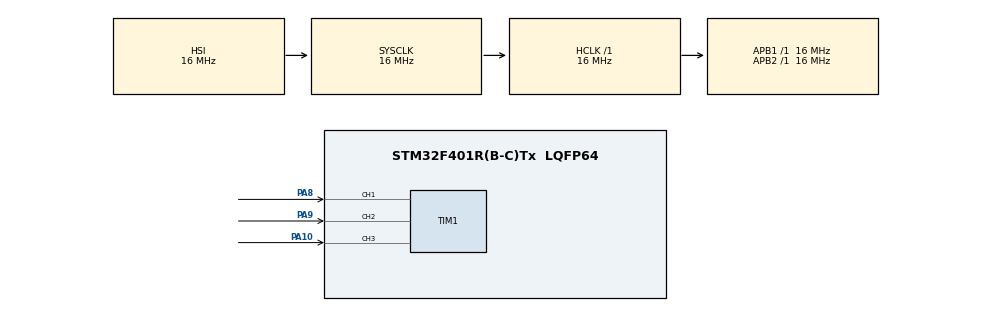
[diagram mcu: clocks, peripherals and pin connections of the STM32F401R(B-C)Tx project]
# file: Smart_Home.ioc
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Mcu.Family=STM32F4
Mcu.Name=STM32F401R(B-C)Tx
Mcu.Package=LQFP64
NVIC.PriorityGroup=NVIC_PRIORITYGROUP_4
PA10.Signal=S_TIM1_CH3
PA8.Signal=S_TIM1_CH1
PA9.Signal=S_TIM1_CH2
ProjectManager.HeapSize=0x200
ProjectManager.StackSize=0x400
ProjectManager.TargetToolchain=STM32CubeIDE
RCC.AHBFreq_Value=16000000
RCC.APB1Freq_Value=16000000
RCC.APB2Freq_Value=16000000
RCC.CortexFreq_Value=16000000
RCC.HSE_VALUE=25000000
RCC.HSI_VALUE=16000000
RCC.LSE_VALUE=32768
RCC.SYSCLKFreq_VALUE=16000000
RCC.VCOOutputFreq_Value=192000000
SH.S_TIM1_CH1.0=TIM1_CH1,Input_Capture1_from_TI1
SH.S_TIM1_CH2.0=TIM1_CH2,Input_Capture2_from_TI2
SH.S_TIM1_CH3.0=TIM1_CH3,Input_Capture3_from_TI3
TIM1.Channel-Input_Capture1_from_TI1=TIM_CHANNEL_1
TIM1.Channel-Input_Capture2_from_TI2=TIM_CHANNEL_2
TIM1.Channel-Input_Capture3_from_TI3=TIM_CHANNEL_3
VP_TIM1_VS_ClockSourceINT.Mode=Internal
board=custom

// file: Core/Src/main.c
/* USER CODE BEGIN Header */
/**
  ******************************************************************************
  * @file           : main.c
  * @brief          : Main program body
  ******************************************************************************
  * @attention
  *
  * Copyright (c) 2024 STMicroelectronics.
  * All rights reserved.
  *
  * This software is licensed under terms that can be found in the LICENSE file
  * in the root directory of this software component.
  * If no LICENSE file comes with this software, it is provided AS-IS.
  *
  ******************************************************************************
  */
/* USER CODE END Header */
#include "main.h"

/* USER CODE BEGIN Includes */

#include "ecu_layer_init.h"

/* USER CODE END Includes */

TIM_HandleTypeDef htim1;

/* USER CODE BEGIN PV */
extern const LED_t LED_CfgType;

Std_ReturnType ret_status = E_NOK;
/* USER CODE END PV */

void SystemClock_Config(void);
static void MX_GPIO_Init(void);
static void MX_TIM1_Init(void);

int main(void)
{

  /* MCU Configuration--------------------------------------------------------*/

  /* Reset of all peripherals, Initializes the Flash interface and the Systick. */
  HAL_Init();

  /* Configure the system clock */
  SystemClock_Config();

  /* Initialize all configured peripherals */
  MX_GPIO_Init();
  MX_TIM1_Init();
  /* USER CODE BEGIN 2 */
  ret_status = LED_Init(&LED_CfgType);
  /* USER CODE END 2 */

  /* Infinite loop */
  while (1)
  {

  }
}

void SystemClock_Config(void)
{
  RCC_OscInitTypeDef RCC_OscInitStruct = {0};
  RCC_ClkInitTypeDef RCC_ClkInitStruct = {0};

  /** Configure the main internal regulator output voltage
  */
  __HAL_RCC_PWR_CLK_ENABLE();
  __HAL_PWR_VOLTAGESCALING_CONFIG(PWR_REGULATOR_VOLTAGE_SCALE2);

  /** Initializes the RCC Oscillators according to the specified parameters
  * in the RCC_OscInitTypeDef structure.
  */
  RCC_OscInitStruct.OscillatorType = RCC_OSCILLATORTYPE_HSI;
  RCC_OscInitStruct.HSIState = RCC_HSI_ON;
  RCC_OscInitStruct.HSICalibrationValue = RCC_HSICALIBRATION_DEFAULT;
  RCC_OscInitStruct.PLL.PLLState = RCC_PLL_NONE;
  if (HAL_RCC_OscConfig(&RCC_OscInitStruct) != HAL_OK)
  {
    Error_Handler();
  }

  /** Initializes the CPU, AHB and APB buses clocks
  */
  RCC_ClkInitStruct.ClockType = RCC_CLOCKTYPE_HCLK|RCC_CLOCKTYPE_SYSCLK
                              |RCC_CLOCKTYPE_PCLK1|RCC_CLOCKTYPE_PCLK2;
  RCC_ClkInitStruct.SYSCLKSource = RCC_SYSCLKSOURCE_HSI;
  RCC_ClkInitStruct.AHBCLKDivider = RCC_SYSCLK_DIV1;
  RCC_ClkInitStruct.APB1CLKDivider = RCC_HCLK_DIV1;
  RCC_ClkInitStruct.APB2CLKDivider = RCC_HCLK_DIV1;

  if (HAL_RCC_ClockConfig(&RCC_ClkInitStruct, FLASH_LATENCY_0) != HAL_OK)
  {
    Error_Handler();
  }
}

static void MX_TIM1_Init(void)
{

  TIM_ClockConfigTypeDef sClockSourceConfig = {0};
  TIM_MasterConfigTypeDef sMasterConfig = {0};
  TIM_IC_InitTypeDef sConfigIC = {0};

  htim1.Instance = TIM1;
  htim1.Init.Prescaler = 0;
  htim1.Init.CounterMode = TIM_COUNTERMODE_UP;
  htim1.Init.Period = 65535;
  htim1.Init.ClockDivision = TIM_CLOCKDIVISION_DIV1;
  htim1.Init.RepetitionCounter = 0;
  htim1.Init.AutoReloadPreload = TIM_AUTORELOAD_PRELOAD_DISABLE;
  if (HAL_TIM_Base_Init(&htim1) != HAL_OK)
  {
    Error_Handler();
  }
  sClockSourceConfig.ClockSource = TIM_CLOCKSOURCE_INTERNAL;
  if (HAL_TIM_ConfigClockSource(&htim1, &sClockSourceConfig) != HAL_OK)
  {
    Error_Handler();
  }
  if (HAL_TIM_IC_Init(&htim1) != HAL_OK)
  {
    Error_Handler();
  }
  sMasterConfig.MasterOutputTrigger = TIM_TRGO_RESET;
  sMasterConfig.MasterSlaveMode = TIM_MASTERSLAVEMODE_DISABLE;
  if (HAL_TIMEx_MasterConfigSynchronization(&htim1, &sMasterConfig) != HAL_OK)
  {
    Error_Handler();
  }
  sConfigIC.ICPolarity = TIM_INPUTCHANNELPOLARITY_RISING;
  sConfigIC.ICSelection = TIM_ICSELECTION_DIRECTTI;
  sConfigIC.ICPrescaler = TIM_ICPSC_DIV1;
  sConfigIC.ICFilter = 0;
  if (HAL_TIM_IC_ConfigChannel(&htim1, &sConfigIC, TIM_CHANNEL_1) != HAL_OK)
  {
    Error_Handler();
  }
  if (HAL_TIM_IC_ConfigChannel(&htim1, &sConfigIC, TIM_CHANNEL_2) != HAL_OK)
  {
    Error_Handler();
  }
  if (HAL_TIM_IC_ConfigChannel(&htim1, &sConfigIC, TIM_CHANNEL_3) != HAL_OK)
  {
    Error_Handler();
  }

}

static void MX_GPIO_Init(void)
{

  /* GPIO Ports Clock Enable */
  __HAL_RCC_GPIOA_CLK_ENABLE();

}

void Error_Handler(void)
{
  __disable_irq();
  while (1)
  {
  }
}
